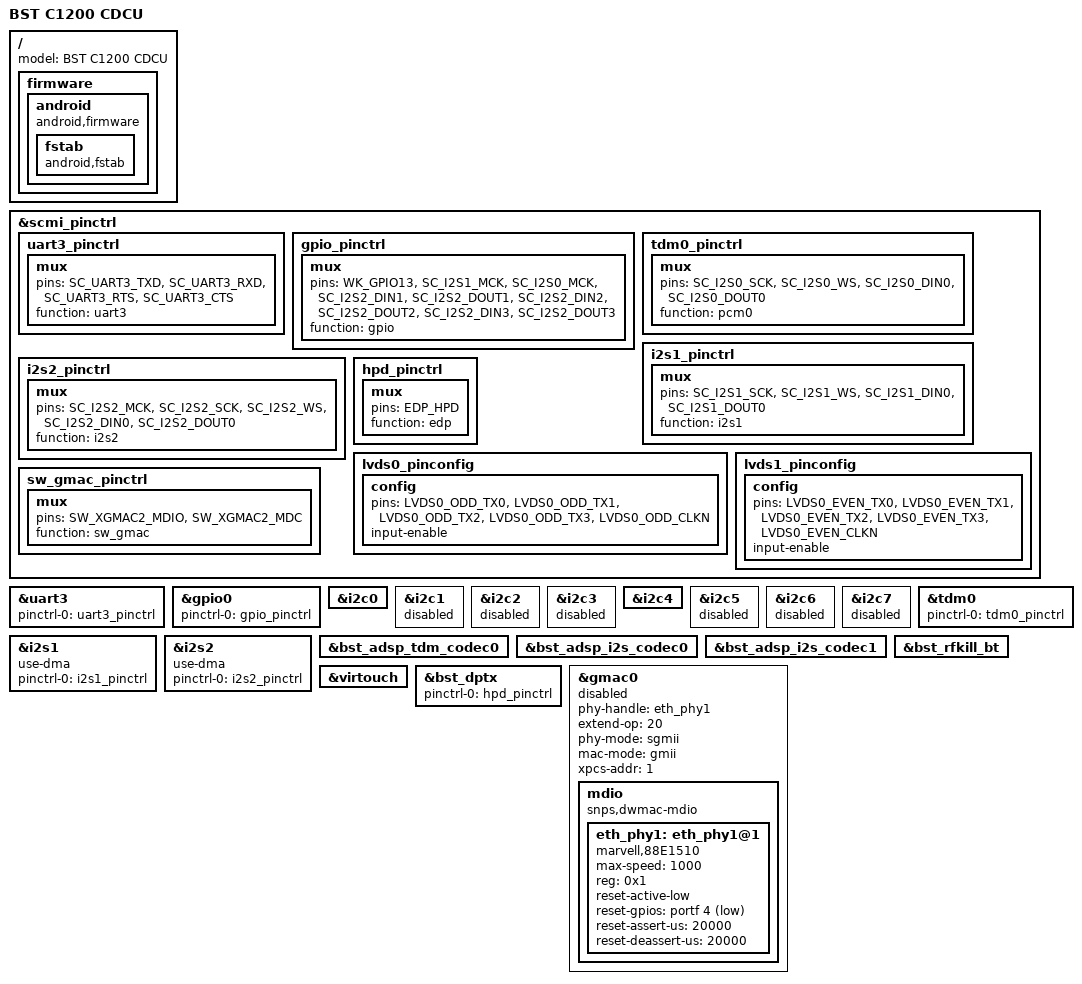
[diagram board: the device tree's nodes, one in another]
/dts-v1/;
/plugin/;

/{
    fragment_root {
        target-path = "/";
        __overlay__ {
            /* This section was used on AOSP v9.0 for defining first-stage fstab records */
            model = "BST C1200 CDCU";
            firmware {
                android {
                    compatible = "android,firmware";

                    fstab {
                        compatible = "android,fstab";
                    };
                };
            };
        };
    };
};
&scmi_pinctrl {    
    uart3_pinctrl:uart3_pinctrl  {
        mux {
            pins = "SC_UART3_TXD", "SC_UART3_RXD","SC_UART3_RTS", "SC_UART3_CTS";
            function = "uart3";
        };
    };

    gpio_pinctrl:gpio_pinctrl {
        mux {
            pins = "WK_GPIO13", "SC_I2S1_MCK", "SC_I2S0_MCK", "SC_I2S2_DIN1", "SC_I2S2_DOUT1",
            "SC_I2S2_DIN2", "SC_I2S2_DOUT2", "SC_I2S2_DIN3", "SC_I2S2_DOUT3";
            function = "gpio";
        };
    };
    tdm0_pinctrl:tdm0_pinctrl  {
        mux {
            pins = "SC_I2S0_SCK", "SC_I2S0_WS", "SC_I2S0_DIN0", "SC_I2S0_DOUT0";
            function = "pcm0";
        };
    };
    i2s1_pinctrl:i2s1_pinctrl  {
        mux {
            pins = "SC_I2S1_SCK", "SC_I2S1_WS", "SC_I2S1_DIN0", "SC_I2S1_DOUT0";
            function = "i2s1";
        };
    };
    i2s2_pinctrl:i2s2_pinctrl  {
        mux {
            pins = "SC_I2S2_MCK", "SC_I2S2_SCK", "SC_I2S2_WS", "SC_I2S2_DIN0", "SC_I2S2_DOUT0";
            function = "i2s2";
        };
    };

    hpd_pinctrl:hpd_pinctrl {
        mux {
            pins = "EDP_HPD";
            function = "edp";
        };
    };
    lvds0_pinconfig:lvds0_pinconfig {
        config {
            pins = "LVDS0_ODD_TX0", "LVDS0_ODD_TX1", "LVDS0_ODD_TX2", "LVDS0_ODD_TX3", "LVDS0_ODD_CLKN";
            input-enable;
        };
    };
    lvds1_pinconfig:lvds1_pinconfig {
        config {
            pins = "LVDS0_EVEN_TX0", "LVDS0_EVEN_TX1", "LVDS0_EVEN_TX2", "LVDS0_EVEN_TX3", "LVDS0_EVEN_CLKN";
            input-enable;
        };
    };
    sw_gmac_pinctrl:sw_gmac_pinctrl {
		mux {
			pins = "SW_XGMAC2_MDIO", "SW_XGMAC2_MDC";    //PAD NAME
			function = "sw_gmac"; 
		};
	};
};
&uart3 {
    status = "okay";
    pinctrl-names = "default";
    pinctrl-0 = <&uart3_pinctrl>;
};
&gpio0 {
	status = "okay";
	pinctrl-names = "default";
	pinctrl-0 = <&gpio_pinctrl>;
};

&i2c0 {
	status = "okay";
};

&i2c1 {
	status = "disable";
};

&i2c2 {
	status = "disable";
};

&i2c3 {
	status = "disable";
};

&i2c4 {
	status = "okay";
};

&i2c5 {
	status = "disable";
};

&i2c6 {
	status = "disable";
};

&i2c7 {
	status = "disable";
};

&tdm0 {
    status = "okay";
    //use-dma;
    pinctrl-names = "default";
    pinctrl-0 = <&tdm0_pinctrl>;
};

&i2s1 {
    status = "okay";
    use-dma;
    pinctrl-names = "default";
    pinctrl-0 = <&i2s1_pinctrl>;
};

&i2s2 {
    status = "okay";
    use-dma;
    pinctrl-names = "default";
    pinctrl-0 = <&i2s2_pinctrl>;
};

&bst_adsp_tdm_codec0 {
    status = "okay";
};

&bst_adsp_i2s_codec0 {
    status = "okay";
};

&bst_adsp_i2s_codec1 {
    status = "okay";
};

&bst_rfkill_bt {
    status = "okay";
};

&virtouch {
	status = "okay";
};

&bst_dptx {
    status = "okay";
    pinctrl-names = "default";
    pinctrl-0 = <&hpd_pinctrl>;
};
&gmac0 {
	status = "disable";
	phy-handle = <&eth_phy1>;
	extend-op = <20>;
	phy-mode = "sgmii";
	mac-mode = "gmii";
    xpcs-addr = <1>;
	/*bypass;  //bool, set: bypass , non set : non bypass
	pinctrl-names = "default"; //bypass
    pinctrl-0 = <&sw_gmac_pinctrl>;*/

	mdio {
		compatible = "snps,dwmac-mdio";
		#address-cells = <1>;
		#size-cells = <0>;
		status = "okay";		
		eth_phy1: eth_phy1@1 {
			compatible = "marvell,88E1510", "ethernet-phy-id0141.0DD1", "ethernet-phy-ieee802.3-c22";
			device_type = "ethernet-phy";
			max-speed = <1000>;
			reg = <0x1>;
			reset-active-low;
			reset-gpios = <&portf 4 1>; //gpio 164
			reset-assert-us = <20000>;
			reset-deassert-us = <20000>;
		};
		
	};
};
